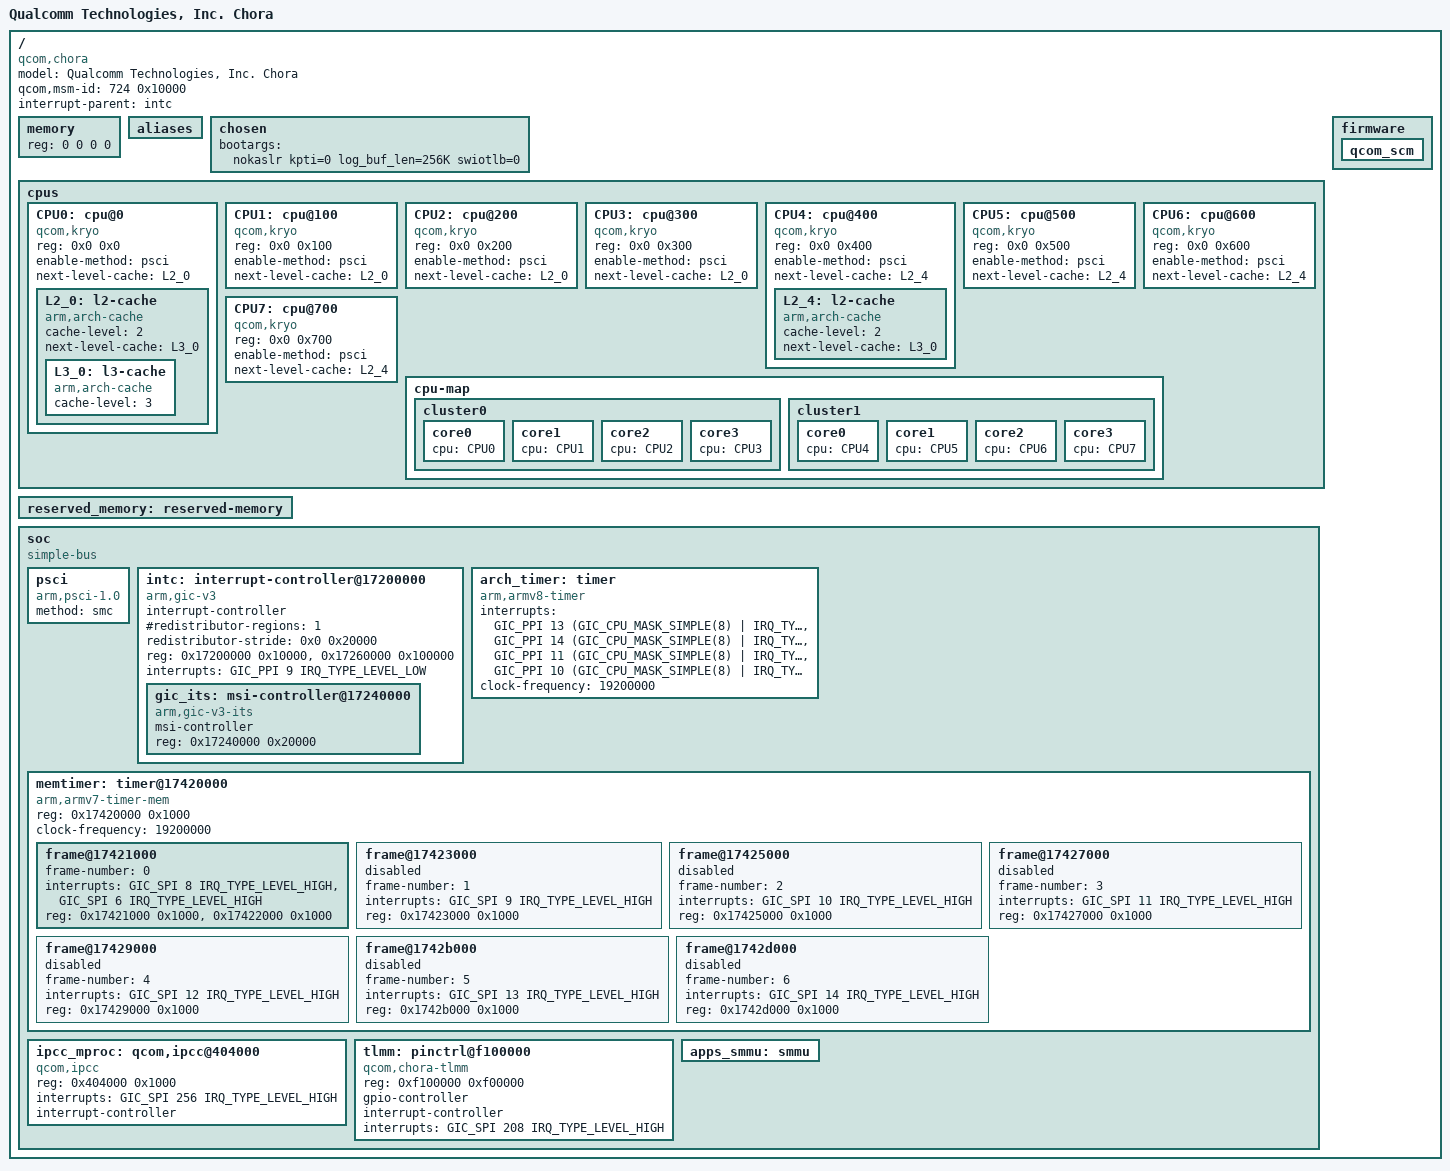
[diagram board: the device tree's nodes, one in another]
// SPDX-License-Identifier: BSD-3-Clause
/*
 * Copyright (c) Qualcomm Technologies, Inc. and/or its subsidiaries.
 */

#include <dt-bindings/interrupt-controller/arm-gic.h>

/ {
	model = "Qualcomm Technologies, Inc. Chora";
	compatible = "qcom,chora";
	qcom,msm-id = <724 0x10000>;
	interrupt-parent = <&intc>;

	#address-cells = <2>;
	#size-cells = <2>;
	memory { device_type = "memory"; reg = <0 0 0 0>; };

	aliases { };

	chosen: chosen {
		bootargs = "nokaslr kpti=0 log_buf_len=256K swiotlb=0";
	};

	cpus {
		#address-cells = <2>;
		#size-cells = <0>;

		CPU0: cpu@0 {
			device_type = "cpu";
			compatible = "qcom,kryo";
			reg = <0x0 0x0>;
			enable-method = "psci";
			next-level-cache = <&L2_0>;

			L2_0: l2-cache {
				compatible = "arm,arch-cache";
				cache-level = <2>;
				next-level-cache = <&L3_0>;

				L3_0: l3-cache {
					compatible = "arm,arch-cache";
					cache-level = <3>;
				};
			};
		};

		CPU1: cpu@100 {
			device_type = "cpu";
			compatible = "qcom,kryo";
			reg = <0x0 0x100>;
			enable-method = "psci";
			next-level-cache = <&L2_0>;
		};

		CPU2: cpu@200 {
			device_type = "cpu";
			compatible = "qcom,kryo";
			reg = <0x0 0x200>;
			enable-method = "psci";
			next-level-cache = <&L2_0>;
		};

		CPU3: cpu@300 {
			device_type = "cpu";
			compatible = "qcom,kryo";
			reg = <0x0 0x300>;
			enable-method = "psci";
			next-level-cache = <&L2_0>;
		};

		CPU4: cpu@400 {
			device_type = "cpu";
			compatible = "qcom,kryo";
			reg = <0x0 0x400>;
			enable-method = "psci";
			next-level-cache = <&L2_4>;

			L2_4: l2-cache {
				compatible = "arm,arch-cache";
				cache-level = <2>;
				next-level-cache = <&L3_0>;
			};
		};

		CPU5: cpu@500 {
			device_type = "cpu";
			compatible = "qcom,kryo";
			reg = <0x0 0x500>;
			enable-method = "psci";
			next-level-cache = <&L2_4>;
		};

		CPU6: cpu@600 {
			device_type = "cpu";
			compatible = "qcom,kryo";
			reg = <0x0 0x600>;
			enable-method = "psci";
			next-level-cache = <&L2_4>;
		};

		CPU7: cpu@700 {
			device_type = "cpu";
			compatible = "qcom,kryo";
			reg = <0x0 0x700>;
			enable-method = "psci";
			next-level-cache = <&L2_4>;
		};

		cpu-map {

			cluster0 {

				core0 {
					cpu = <&CPU0>;
				};

				core1 {
					cpu = <&CPU1>;
				};

				core2 {
					cpu = <&CPU2>;
				};

				core3 {
					cpu = <&CPU3>;
				};
			};

			cluster1 {

				core0 {
					cpu = <&CPU4>;
				};

				core1 {
					cpu = <&CPU5>;
				};

				core2 {
					cpu = <&CPU6>;
				};

				core3 {
					cpu = <&CPU7>;
				};
			};
		};
	};

	firmware: firmware {
		qcom_scm: qcom_scm { };
	};

	reserved_memory: reserved-memory { };

	soc: soc { };
};

&soc {
	#address-cells = <1>;
	#size-cells = <1>;
	ranges = <0 0 0 0xffffffff>;
	compatible = "simple-bus";

	psci: psci {
		compatible = "arm,psci-1.0";
		method = "smc";
	};

	intc: interrupt-controller@17200000 {
		compatible = "arm,gic-v3";
		#interrupt-cells = <3>;
		interrupt-controller;
		#redistributor-regions = <1>;
		redistributor-stride = <0x0 0x20000>;
		reg = <0x17200000 0x10000>,	/* GICD */
		      <0x17260000 0x100000>;	/* GICR * 8 */
		interrupts = <GIC_PPI 9 IRQ_TYPE_LEVEL_LOW>;

		#address-cells = <1>;
		#size-cells = <1>;
		gic_its: msi-controller@17240000 {
			compatible = "arm,gic-v3-its";
			msi-controller;
			#msi-cells = <1>;
			reg = <0x17240000 0x20000>;
		};
	};

	arch_timer: timer {
		compatible = "arm,armv8-timer";
		interrupts = <GIC_PPI 13 (GIC_CPU_MASK_SIMPLE(8) | IRQ_TYPE_LEVEL_LOW)>,
			     <GIC_PPI 14 (GIC_CPU_MASK_SIMPLE(8) | IRQ_TYPE_LEVEL_LOW)>,
			     <GIC_PPI 11 (GIC_CPU_MASK_SIMPLE(8) | IRQ_TYPE_LEVEL_LOW)>,
			     <GIC_PPI 10 (GIC_CPU_MASK_SIMPLE(8) | IRQ_TYPE_LEVEL_LOW)>;
		clock-frequency = <19200000>;
	};

	memtimer: timer@17420000 {
		#address-cells = <1>;
		#size-cells = <1>;
		ranges;
		compatible = "arm,armv7-timer-mem";
		reg = <0x17420000 0x1000>;
		clock-frequency = <19200000>;

		frame@17421000 {
			frame-number = <0>;
			interrupts = <GIC_SPI 8 IRQ_TYPE_LEVEL_HIGH>,
				     <GIC_SPI 6 IRQ_TYPE_LEVEL_HIGH>;
			reg = <0x17421000 0x1000>,
			      <0x17422000 0x1000>;
		};

		frame@17423000 {
			frame-number = <1>;
			interrupts = <GIC_SPI 9 IRQ_TYPE_LEVEL_HIGH>;
			reg = <0x17423000 0x1000>;
			status = "disabled";
		};

		frame@17425000 {
			frame-number = <2>;
			interrupts = <GIC_SPI 10 IRQ_TYPE_LEVEL_HIGH>;
			reg = <0x17425000 0x1000>;
			status = "disabled";
		};

		frame@17427000 {
			frame-number = <3>;
			interrupts = <GIC_SPI 11 IRQ_TYPE_LEVEL_HIGH>;
			reg = <0x17427000 0x1000>;
			status = "disabled";
		};

		frame@17429000 {
			frame-number = <4>;
			interrupts = <GIC_SPI 12 IRQ_TYPE_LEVEL_HIGH>;
			reg = <0x17429000 0x1000>;
			status = "disabled";
		};

		frame@1742b000 {
			frame-number = <5>;
			interrupts = <GIC_SPI 13 IRQ_TYPE_LEVEL_HIGH>;
			reg = <0x1742b000 0x1000>;
			status = "disabled";
		};

		frame@1742d000 {
			frame-number = <6>;
			interrupts = <GIC_SPI 14 IRQ_TYPE_LEVEL_HIGH>;
			reg = <0x1742d000 0x1000>;
			status = "disabled";
		};
	};

	ipcc_mproc: qcom,ipcc@404000 {
		compatible = "qcom,ipcc";
		reg = <0x404000 0x1000>;
		interrupts = <GIC_SPI 256 IRQ_TYPE_LEVEL_HIGH>;
		interrupt-controller;
		#interrupt-cells = <3>;
		#mbox-cells = <2>;
	};

	tlmm: pinctrl@f100000 {
		compatible = "qcom,chora-tlmm";
		reg = <0xf100000 0xf00000>;
		gpio-controller;
		#gpio-cells = <2>;
		interrupt-controller;
		#interrupt-cells = <2>;
		interrupts = <GIC_SPI 208 IRQ_TYPE_LEVEL_HIGH>;
		/* TODO: Add qcom,gpios-reserved */
	};

	apps_smmu: smmu {};
};

#include "chora-pinctrl.dtsi"
